# PIC32CM5112GC00048 device description
Architecture: CORTEX-M23; Family: PIC32CM; Series: PIC32CMGC00
Registers are 32-bit, read-write, reset 0x0 unless marked. A register's access mark holds for its fields unless they carry their own. Offsets are from the block's base; [hi:lo] are bit positions; {n}, {i} and the like mark numbered series; 'fields as' and 'values as' point back to an identical list.

## ICB — Implementation Control Block
Instances: ICB 0xE000E000
0x04 ICTR ro reset not defined — Interrupt Controller Type Register
  [3:0] INTLINESNUM — Interrupt line set number
0x08 ACTLR reset not defined — Auxiliary Control Register

## MCLK — Polaris Main Clock Controller
Instances: MCLK 0x4400A000
0x00 INTENCLR (atomic clear) — Interrupt Enable Clear Register
  [0] CKRDY — Clock Ready Interrupt Enable Clear
    0=The Clock Ready interrupt is disabled; 1=The Clock Ready interrupt is enabled
0x04 INTENSET (atomic set) — Interrupt Enable Set Register
  [0] CKRDY — Clock Ready Interrupt Enable Set
    values as INTENCLR.CKRDY
0x08 INTFLAG wo reset 0x1 (atomic clear) — Interrupt Flag Status Register
  [0] CKRDY — Clock Ready Interrupt Flag
{0xC+4i} CLKDIV[{i}] (i=0..2) — Clock Divider Control n Register
  [7:0] DIV — Clock Domain n Division Factor
    1=Divide by 1; 2=Divide by 2; 4=Divide by 4; 8=Divide by 8; 16=Divide by 16; 32=Divide by 32; 64=Divide by 64; 128=Divide by 128
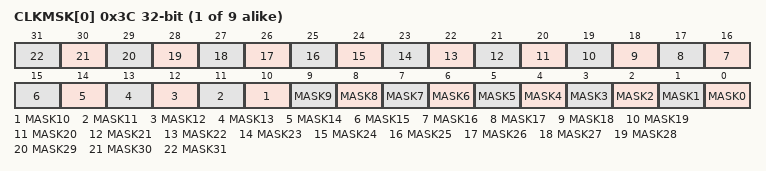
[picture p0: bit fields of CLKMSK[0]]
{0x3C+4i} CLKMSK[{i}] (i=0..8) — Peripheral Clock Enable Mask n Register
  [all] fields
    0=Peripheral clock mclk_clk_periph[n*32+x] stopped; 1=Peripheral clock mclk_clk_periph[n*32+x] enabled
  [n] MASK{n} (n=0..31) — Peripheral Clock Enable Mask

## MCRAMC — Multi-Channel RAM Controller
Instances: MCRAMC 0x4402C000
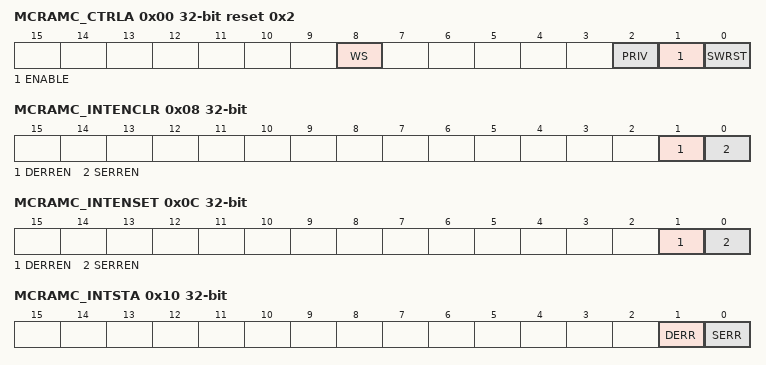
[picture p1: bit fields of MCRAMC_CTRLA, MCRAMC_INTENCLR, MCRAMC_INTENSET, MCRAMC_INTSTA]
0x00 MCRAMC_CTRLA reset 0x2 — Control Enable A Register
  [8] WS — Wait State Enable
  [2] PRIV — Priviledged Access Enable
  [1] ENABLE — ECC Decoder Enable
    0=ECC decoding is disabled; 1=ECC decoding is enabled
  [0] SWRST — Software Reset
    0=No effect; 1=Reset the MCRAMC. A software-triggered hardware reset of the MCRAMC user interface is performed.
0x08 MCRAMC_INTENCLR (atomic clear) — Interrupt Enable Clear Register
  [1] DERREN — Double Bit Error Interrupt Enable, Clear
  [0] SERREN — Single Bit Error Interrupt Enable, Clear
0x0C MCRAMC_INTENSET (atomic set) — Interrupt Enable Set Register
  [1] DERREN — Double Bit Error Interrupt Enable, Set
  [0] SERREN — Single Bit Error Interrupt Enable, Set
0x10 MCRAMC_INTSTA (atomic clear) — Interrupt Status Register
  [1] DERR — Double Bit Error
  [0] SERR — Single Bit Error
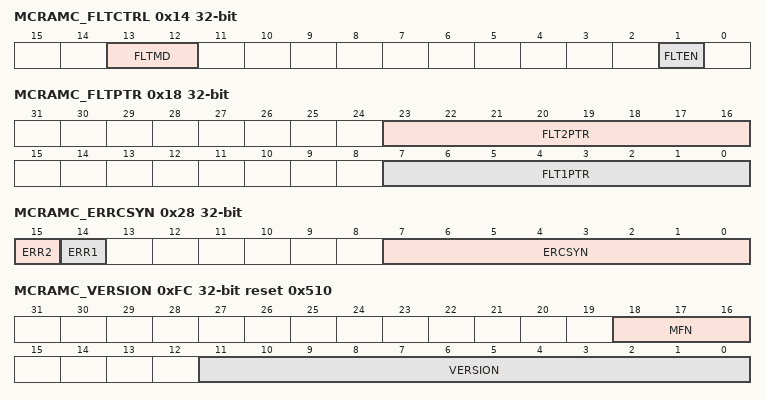
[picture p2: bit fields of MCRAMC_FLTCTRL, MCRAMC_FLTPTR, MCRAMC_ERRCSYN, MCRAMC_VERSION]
0x14 MCRAMC_FLTCTRL — Fault Injection Control Register
  [13:12] FLTMD — Fault Injection Mode
  [1] FLTEN — Fault Injection Enabled
    0=Disables fault injection; 1=Enables fault injection at FLTADR address offset as selected by FLTMD and FLTxPTR
0x18 MCRAMC_FLTPTR — Fault Injection Pointer Register
  [23:16] FLT2PTR — Double Fault Injection Bit Pointer
  [7:0] FLT1PTR — Single Fault Injection Bit Pointer
0x1C MCRAMC_FLTADR — Fault Injection Address Register
  [23:0] FLTADR — Fault Address Offset
0x20 MCRAMC_ERRCADR ro — Error Capture Address Register
  [23:0] ERCADR — ECC SECDED Error Capture Address
0x24 MCRAMC_ERRCPAR ro — Error Capture Parity Register
  [7:0] ERCPAR — ECC SECDED Error Capture Parity
0x28 MCRAMC_ERRCSYN ro — Error Capture Syndrome Register
  [15] ERR2 — ECC Double Bit Error
    0=Not a Double bit error; 1=Double bit error
  [14] ERR1 — ECC Single Bit Error
  [7:0] ERCSYN — ECC SECDED Error Capture Syndrome
    0=Not a Single bit error; 1=Single bit error
0xFC MCRAMC_VERSION ro reset 0x510 — Version Register
  [18:16] MFN — Metal Fix Number
  [11:0] VERSION — MCRAMC Version

## MPU — Memory Protection Unit
Instances: MPU 0xE000ED90
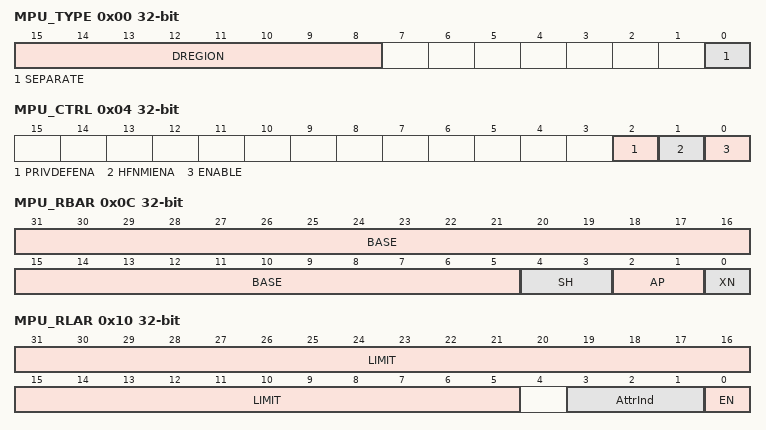
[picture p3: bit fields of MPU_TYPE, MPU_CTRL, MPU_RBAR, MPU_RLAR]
0x00 MPU_TYPE ro reset not defined
  [15:8] DREGION — Number of MPU data regions
  [0] SEPARATE — Separate instructions and data address regions
0x04 MPU_CTRL reset not defined — MPU Control Register
  [2] PRIVDEFENA — Privileged default enable
  [1] HFNMIENA — HardFault, NMI enable
  [0] ENABLE — MPU enable
0x08 MPU_RNR reset not defined — MPU Region Number Register
  [7:0] REGION — Selected region number
0x0C MPU_RBAR reset not defined — MPU Region Base Address Register
  [31:5] BASE — Base address
  [4:3] SH — Shareability
    0=NO (Non-shareable); 2=OUTER (Outer shareable); 3=INNER (Inner shareable)
  [2:1] AP — Access permissions
    0=RWPRIV (Read/write by privileged code only); 1=RWANY (Read/write by any privilege level); 2=RPRIV (Read-only by privileged code only); 3=RANY (Read-only by any privilege level)
  [0] XN — Execute Never
0x10 MPU_RLAR reset not defined — MPU Region Limit Address Register
  [31:5] LIMIT — Limit address
  [3:1] AttrInd — Attribute Index
  [0] EN — Region enable
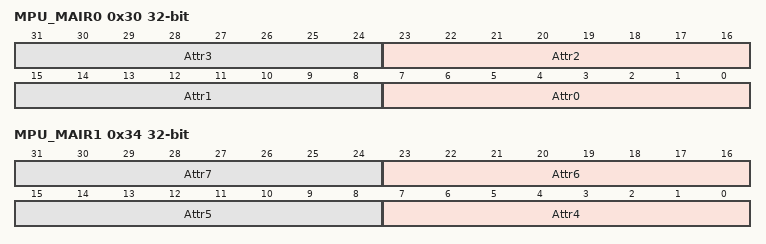
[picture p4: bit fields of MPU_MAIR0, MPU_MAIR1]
0x30 MPU_MAIR0 reset not defined — MPU Memory Attribute Indirection Register 0
  [8n+7:8n] Attr{n} (n=0..3) — Attribute of MPU region {n}
0x34 MPU_MAIR1 reset not defined — MPU Memory Attribute Indirection Register 1
  [8n-25:8n-32] Attr{n} (n=4..7) — Attribute of MPU region {n}
